# Q32M210 register map
File version: 1.0
Registers are 32-bit, read-write, no defined reset value unless marked. A register's access mark holds for its fields unless they carry their own. Offsets are from the block's base; [hi:lo] are bit positions; {n}, {i} and the like mark numbered series.

## USB_Interface_Configuration_and_Control
Base 0x40001784
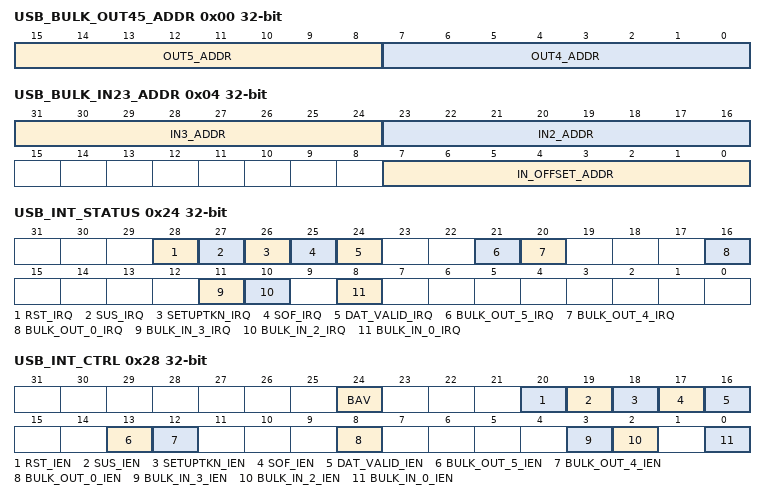
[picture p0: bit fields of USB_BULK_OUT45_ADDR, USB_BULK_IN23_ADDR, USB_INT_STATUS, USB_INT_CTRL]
0x00 USB_BULK_OUT45_ADDR — USB Bulk 4 and 5 OUT start address register
  [15:8] OUT5_ADDR — Start address bits for EP5 OUT endpoint buffer. Must be initialized to 0x30. This field is write-only; all reads return 0.
    48=USB_BULK_OUT5_ADDR_VALUE (Start address for the bulk output buffer of endpoint 5)
  [7:0] OUT4_ADDR — Start address bits for EP4 OUT endpoint buffer. Must be initialized to 0x10. This field is write-only; all reads return 0.
    16=USB_BULK_OUT4_ADDR_VALUE (Start address for the bulk output buffer of endpoint 4)
0x04 USB_BULK_IN23_ADDR — USB Bulk 2 and 3 IN start address register
  [31:24] IN3_ADDR — Start address bits for EP3 IN endpoint buffer. Must be initialized to 0x30. This field is write-only; all reads return 0.
    48=USB_BULK_IN3_ADDR_VALUE (Start address for the bulk input buffer of endpoint 3)
  [23:16] IN2_ADDR — Start address bits for EP2 IN endpoint buffer. Must be initialized to 0x10. This field is write-only; all reads return 0.
    16=USB_BULK_IN2_ADDR_VALUE (Start address for the bulk input buffer of endpoint 2)
  [7:0] IN_OFFSET_ADDR — Start address offset for EP0 IN endpoint buffer. Must be initialized to 0x28. This field is write-only; all reads return 0.
    40=USB_BULK_OFFSET_ADDR_VALUE (Start address offset for bulk input endpoints)
0x0C USB_CLOCK_GATE
  [7:0] CLOCK_GATE — Write any value to this register to enable USB clock gating
0x24 USB_INT_STATUS — USB Interrupt Status register
  [28] RST_IRQ — USB reset interrupt request. The USB controller sets this bit to 1 when it detects a USB bus reset.
    1=USB_RST_IRQ_CLEAR (Clears the USB reset interrupt request)
  [27] SUS_IRQ — USB suspend interrupt request. The USB controller sets this bit to 1 when it detects USB suspend signalling.
    1=USB_SUS_IRQ_CLEAR (Clears the USB suspend interrupt request)
  [26] SETUPTKN_IRQ — SETUP token interrupt request. The USB controller sets this bit to 1 when it receives a SETUP token.
    1=USB_SETUPTKN_IRQ_CLEAR (Clears the SETUP token interrupt request)
  [25] SOF_IRQ — Start-of-Frame interrupt request. The USB controller sets this bit to 1 when it receives a SOF packet.
    1=USB_SOF_IRQ_CLEAR (Clears the Start-Of-Frame interrupt request)
  [24] DAT_VALID_IRQ — SETUP data valid interrupt request. The USB controller sets this bit to 1 when it receives an error-free SETUP data packet.
    1=USB_DAT_VALID_IRQ_CLEAR (Clears SETUP data valid interrupt request)
  [21] BULK_OUT_5_IRQ — Indicate that an EP5 OUT interrupt request occurred
    1=USB_BULK_OUT_5_IRQ_CLEAR (Clears the Bulk 5 OUT IRQ)
  [20] BULK_OUT_4_IRQ — Indicate that an EP4 OUT interrupt request occurred
    1=USB_BULK_OUT_4_IRQ_CLEAR (Clears the Bulk 4 OUT IRQ)
  [16] BULK_OUT_0_IRQ — Indicate that an EP0 OUT interrupt request occurred
    1=USB_BULK_OUT_0_IRQ_CLEAR (Clears the Bulk 0 OUT IRQ)
  [11] BULK_IN_3_IRQ — Indicate that an EP3 IN interrupt request occurred
    1=USB_BULK_IN_3_IRQ_CLEAR (Clears the Bulk 3 IN IRQ)
  [10] BULK_IN_2_IRQ — Indicate that an EP2 IN interrupt request occurred
    1=USB_BULK_IN_2_IRQ_CLEAR (Clears the Bulk 2 IN IRQ)
  [8] BULK_IN_0_IRQ — Indicate that an EP0 IN interrupt request occurred
    1=USB_BULK_IN_0_IRQ_CLEAR (Clears the Bulk 0 IN IRQ)
0x28 USB_INT_CTRL — USB Interrupt Control register
  [24] BAV — Breakpoint and autovector register. This field must be set to 1.
    1=USB_BAV_ENABLE (Enable autovector feature for USB interrupts (MCU must support autovectoring)); 0=USB_BAV_DISABLE (Disable autovector features for USB interrupts)
  [20] RST_IEN — USB reset interrupt enable
    1=USB_RST_IEN_ENABLE (Enables the USB reset interrupt); 0=USB_RST_IEN_DISABLE (Disables the USB reset interrupt)
  [19] SUS_IEN — USB suspend interrupt enable
    1=USB_SUS_IEN_ENABLE (Enables the USB suspend interrupt); 0=USB_SUS_IEN_DISABLE (Disables the USB suspend interrupt)
  [18] SETUPTKN_IEN — SETUP token interrupt enable
    1=USB_SETUPTKN_IEN_ENABLE (Enables the SETUP token interrupt); 0=USB_SETUPTKN_IEN_DISABLE (Disables the SETUP token interrupt)
  [17] SOF_IEN — Start-Of-Frame interrupt enable
    1=USB_SOF_IEN_ENABLE (Enables the Start-Of-Frame interrupt); 0=USB_SOF_IEN_DISABLE (Disables the Start-Of-Frame interrupt)
  [16] DAT_VALID_IEN — SETUP data valid interrupt enable
    1=USB_DAT_VALID_IEN_ENABLE (Enables the SETUP data valid interrupt); 0=USB_DAT_VALID_IEN_DISABLE (Disables the SETUP data valid interrupt)
  [13] BULK_OUT_5_IEN — EP5 OUT interrupt enable
    1=USB_BULK_OUT_5_IEN_ENABLE (Enables the Bulk 5 OUT interrupt); 0=USB_BULK_OUT_5_IEN_DISABLE (Disables the Bulk 5 OUT interrupt)
  [12] BULK_OUT_4_IEN — EP4 OUT interrupt enable
    1=USB_BULK_OUT_4_IEN_ENABLE (Enables the Bulk 4 OUT interrupt); 0=USB_BULK_OUT_4_IEN_DISABLE (Disables the Bulk 4 OUT interrupt)
  [8] BULK_OUT_0_IEN — EP0 OUT interrupt enable
    1=USB_BULK_OUT_0_IEN_ENABLE (Enables the Bulk 0 OUT interrupt); 0=USB_BULK_OUT_0_IEN_DISABLE (Disables the Bulk 0 OUT interrupt)
  [3] BULK_IN_3_IEN — EP3 IN interrupt enable
    1=USB_BULK_IN_3_IEN_ENABLE (Enables the Bulk 3 IN interrupt); 0=USB_BULK_IN_3_IEN_DISABLE (Disables the Bulk 3 IN interrupt)
  [2] BULK_IN_2_IEN — EP2 IN interrupt enable
    1=USB_BULK_IN_2_IEN_ENABLE (Enables the Bulk 2 IN interrupt); 0=USB_BULK_IN_2_IEN_DISABLE (Disables the Bulk 2 IN interrupt)
  [0] BULK_IN_0_IEN — EP0 IN interrupt enable
    1=USB_BULK_IN_0_IEN_ENABLE (Enables the Bulk 0 IN interrupt); 0=USB_BULK_IN_0_IEN_DISABLE (Disables the Bulk 0 IN interrupt)
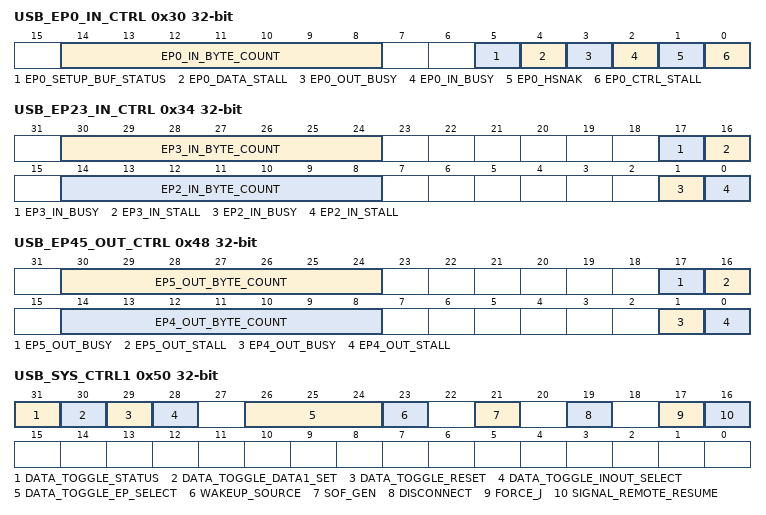
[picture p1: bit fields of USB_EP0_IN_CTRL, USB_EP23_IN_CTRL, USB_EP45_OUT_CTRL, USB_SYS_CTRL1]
0x30 USB_EP0_IN_CTRL — USB IN Endpoint 0 Control and Status register
  [14:8] EP0_IN_BYTE_COUNT — Indicates how many bytes will be transmitted from the EP0 IN endpoint. Writing any value (including 0) to this field clears the EP0_IN_BUSY bit and sends the data on the endpoint.
  [5] EP0_SETUP_BUF_STATUS — Indicates that the SETUP buffer contents were changed. If this bit is 1, the SETUP buffer was changed. This bit is automatically cleared when USB controller receives a SETUP data packet.
  [4] EP0_DATA_STALL — EP0 stall during the data stage. If this bit is 1, the USB controller sends a STALL handshake for any IN or OUT token. Automatically cleared when a SETUP token arrives. The ARM Cortex-M3 processor should set this bit after the last successful transaction in the data stage.
  [3] EP0_OUT_BUSY — EP0 OUT endpoint busy bit. If this bit is 1, the USB controller takes control of the EP0 OUT endpoint buffer. If this bit is 0, the ARM Cortex-M3 processor takes control of the EP0 OUT endpoint buffer. Automatically cleared when a SETUP token arrives. The ARM Cortex-M3 processor sets this bit by writing a dummy value to USB_EP0_OUT_BYTE_COUNT.
  [2] EP0_IN_BUSY — EP0 IN endpoint busy bit. If this bit is 1, the USB controller takes control of the EP0 IN endpoint buffer. If this bit is 0, the ARM Cortex-M3 processor takes control of the EP0 IN endpoint buffer. Automatically cleared when a SETUP token arrives. The ARM Cortex-M3 processor sets this bit by reloading USB_EP0_IN_BYTE_COUNT.
  [1] EP0_HSNAK — EP0 handshake NAK. If this bit is set to 1, the USB controller responds with a NAK handshake for every packet in the status stage. Automatically set when a SETUP token arrives.
  [0] EP0_CTRL_STALL — EP0 stall during the data or handshake phases of the CONTROL transfer. If this bit is set to 1, the USB controller sends a STALL handshake for any IN or OUT token. Automatically cleared when a SETUP token arrives.
0x34 USB_EP23_IN_CTRL — USB IN Endpoint 2 and 3 Control and Status register
  [30:24] EP3_IN_BYTE_COUNT — Indicates how many bytes will be transmitted from the EP3 IN endpoint. Writing any value (including 0) to this field clears the EP3_IN_BUSY bit and sends the data on the endpoint.
  [17] EP3_IN_BUSY — EP3 IN endpoint busy bit. If this bit is 1, the USB controller takes control of the EP3 IN endpoint buffer. If this bit is 0, the ARM Cortex-M3 processor takes control of the EP3 IN endpoint buffer. Automatically cleared when a SETUP token arrives.
  [16] EP3_IN_STALL — EP3 IN endpoint stall bit. If this bit is 1, the USB controller returns a STALL handshake for all requests to EP3.
  [14:8] EP2_IN_BYTE_COUNT — Indicates how many bytes will be transmitted from the EP2 IN endpoint. Writing any value (including 0) to this field clears the EP2_IN_BUSY bit and sends the data on the endpoint.
  [1] EP2_IN_BUSY — EP2 IN endpoint busy bit. If this bit is 1, the USB controller takes control of the EP2 IN endpoint buffer. If this bit is 0, the ARM Cortex-M3 processor takes control of the EP2 IN endpoint buffer. Automatically cleared when a SETUP token arrives.
  [0] EP2_IN_STALL — EP2 IN endpoint stall bit. If this bit is 1, the USB controller returns a STALL handshake for all requests to EP2.
0x40 USB_EP0_OUT_CTRL — USB OUT Endpoint 0 Control and Status register
  [14:8] EP0_OUT_BYTE_COUNT — Indicates how many bytes were received by the EP0 OUT endpoint. Write a new value to this field to clear the EP0_OUT_BUSY bit and make the endpoint ready to receive more data.
0x48 USB_EP45_OUT_CTRL — USB OUT Endpoint 4 and 5 Control and Status register
  [30:24] EP5_OUT_BYTE_COUNT — Indicates how many bytes were received by the EP5 OUT endpoint. Write a new value to this field to set the EP5_OUT_BUSY bit and make the endpoint ready to receive more data.
  [17] EP5_OUT_BUSY — EP5 OUT endpoint busy bit. If this bit is 1, the USB controller takes control of the EP5 OUT endpoint buffer. If this bit is 0, the ARM Cortex-M3 processor takes control of the EP5 OUT endpoint buffer. Automatically cleared when a SETUP token arrives.
  [16] EP5_OUT_STALL — EP5 OUT endpoint stall bit. If this bit is 1, the USB controller returns a STALL handshake for all requests to EP5.
  [14:8] EP4_OUT_BYTE_COUNT — Indicates how many bytes were received by the EP4 OUT endpoint. Write a new value to this field to set the EP4_OUT_BUSY bit and make the endpoint ready to receive more data.
  [1] EP4_OUT_BUSY — EP4 OUT endpoint busy bit. If this bit is 1, the USB controller takes control of the EP4 OUT endpoint buffer. If this bit is 0, the ARM Cortex-M3 processor takes control of the EP4 OUT endpoint buffer. Automatically cleared when a SETUP token arrives.
  [0] EP4_OUT_STALL — EP4 OUT endpoint stall bit. If this bit is 1, the USB controller returns a STALL handshake for all requests to EP4.
0x50 USB_SYS_CTRL1 — USB Control and Status register 1
  [31] DATA_TOGGLE_STATUS — If this bit is 1, it means that the data toggle for selected endpoints is set to DATA1. Otherwise, it means that the data toggle is set to DATA0.
  [30] DATA_TOGGLE_DATA1_SET — Sets the data toggle to DATA1.
  [29] DATA_TOGGLE_RESET — Resets the data toggle to DATA0.
  [28] DATA_TOGGLE_INOUT_SELECT — Selects IN or OUT endpoint
  [26:24] DATA_TOGGLE_EP_SELECT — Select the number of endpoints to support data toggle
  [23] WAKEUP_SOURCE — Wakeup source. If this bit is 1, the wakeup was initiated by the microcontroller by setting the REMOTE_WAKEUP bit in the USB_CTRL register. If this bit is 0, the wakeup was initiated by the USB host.
  [21] SOF_GEN — If this bit is 1, an internal Start-of-Frame timer is used to generate the Start-of-Frame interrupt.
  [19] DISCONNECT — Signals a disconnect. If this bit is 1, the external USB transceiver disconnects a microcontroller by disconnecting the D+ or D- pull-up resistor.
    1=USB_DISCONNECT_ENABLE (Signals a disconnect); 0=USB_DISCONNECT_DISABLE (Removes disconnect signal)
  [17] FORCE_J — Only use this in the suspend state. The ARM Cortex-M3 processor uses it to drive the J state on the USB lines.
    1=USB_FORCE_J_ENABLE (Causes the CUSB to set the J state on the USB); 0=USB_FORCE_J_DISABLE (Removes J state setting)
  [16] SIGNAL_REMOTE_RESUME — Signal remote device resume. If the ARM Cortex-M3 processor sets this bit to 1, the USB controller sets the K state on the USB lines.
    1=USB_SIGNAL_REMOTE_RESUME_ENABLE (Causes the CUSB to set K state on the USB); 0=USB_SIGNAL_REMOTE_RESUME_DISABLE (Removes K state setting)
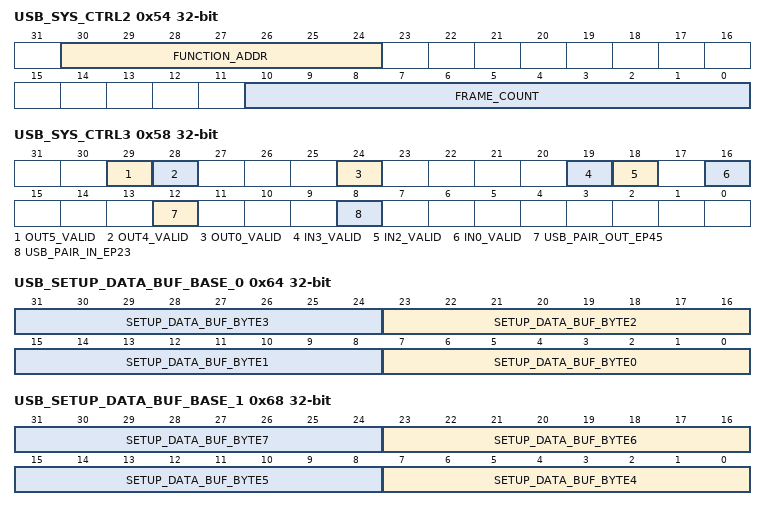
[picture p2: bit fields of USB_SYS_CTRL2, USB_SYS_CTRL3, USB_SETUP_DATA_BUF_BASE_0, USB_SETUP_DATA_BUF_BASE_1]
0x54 USB_SYS_CTRL2 — USB Control and Status register 2
  [30:24] FUNCTION_ADDR — The register contains the function address that was sent by the host during USB enumeration
  [10:0] FRAME_COUNT — The register contains the frame count from the most recent Start-of-Frame token
0x58 USB_SYS_CTRL3 — USB Control and Status register 3
  [29] OUT5_VALID — Indicate if EP5 OUT endpoint is valid for USB transfers
    1=USB_OUT5_VALID_ENABLE (Activates the Bulk 5 OUT endpoint); 0=USB_OUT5_VALID_DISABLE (De-activates the Bulk 5 OUT endpoint)
  [28] OUT4_VALID — Indicate if EP4 OUT endpoint is valid for USB transfers
    1=USB_OUT4_VALID_ENABLE (Activates the Bulk 4 OUT endpoint); 0=USB_OUT4_VALID_DISABLE (De-activates the Bulk 4 OUT endpoint)
  [24] OUT0_VALID — Indicate if EP0 OUT endpoint is valid for USB transfers
    1=USB_OUT0_VALID_ENABLE (Activates the 0 OUT endpoint); 0=USB_OUT0_VALID_DISABLE (De-activates the 0 OUT endpoint)
  [19] IN3_VALID — Indicate if EP3 IN endpoint is valid for USB transfers
    1=USB_IN3_VALID_ENABLE (Activates the Bulk 3 IN endpoint); 0=USB_IN3_VALID_DISABLE (De-activates the Bulk 3 IN endpoint)
  [18] IN2_VALID — Indicate if EP2 IN endpoint is valid for USB transfers
    1=USB_IN2_VALID_ENABLE (Activates the Bulk 2 IN endpoint); 0=USB_IN2_VALID_DISABLE (De-activates the Bulk 2 IN endpoint)
  [16] IN0_VALID — Indicate if EP0 IN endpoint is valid for USB transfers
    1=USB_IN0_VALID_ENABLE (Activates the 0 IN endpoint); 0=USB_IN0_VALID_DISABLE (De-activates the 0 IN endpoint)
  [12] USB_PAIR_OUT_EP45 — Enable and disable the pairing of EP4 and EP5 OUT endpoints
    1=USB_PAIR_OUT_EP45_ENABLE (Enables OUT endpoint 4 and 5 pairing); 0=USB_PAIR_OUT_EP45_DISABLE (Disables OUT endpoint 4 and 5 pairing)
  [8] USB_PAIR_IN_EP23 — Enable and disable the pairing of EP2 and EP3 IN endpoints
    1=USB_PAIR_IN_EP23_ENABLE (Enables IN endpoint 2 and 3 pairing); 0=USB_PAIR_IN_EP23_DISABLE (Disables IN endpoint 2 and 3 pairing)
0x64 USB_SETUP_DATA_BUF_BASE_0 — USB Setup Data Buffer base Lower
  [8n+7:8n] SETUP_DATA_BUF_BYTE{n} (n=0..3) — Byte {n} of the SETUP data packet
0x68 USB_SETUP_DATA_BUF_BASE_1 — USB Setup Data Buffer base Higher
  [8n-25:8n-32] SETUP_DATA_BUF_BYTE{n} (n=4..7) — Byte {n} of the SETUP data packet
